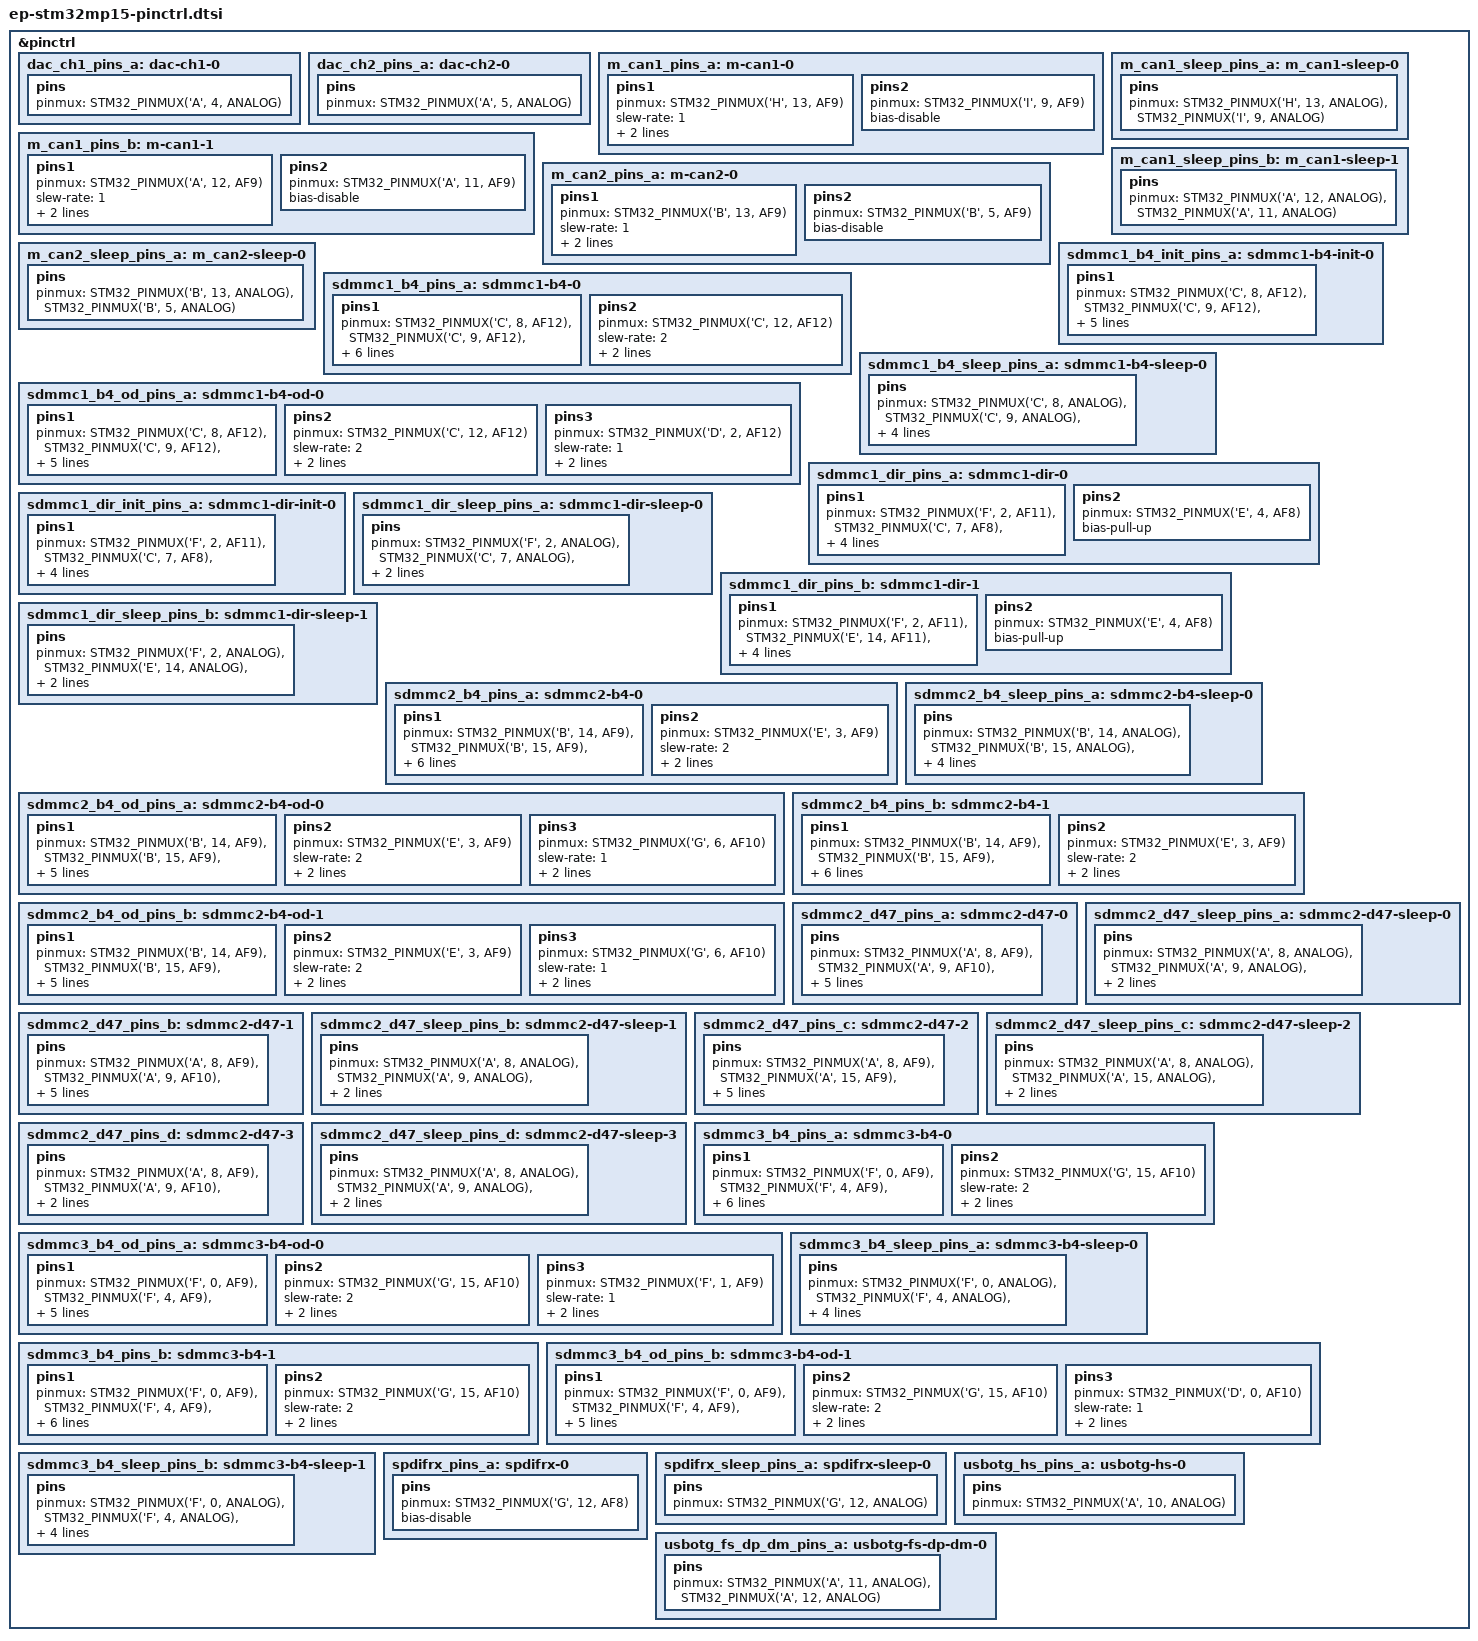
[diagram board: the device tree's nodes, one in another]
// SPDX-License-Identifier: (GPL-2.0+ OR BSD-3-Clause)
/*
 * Copyright (C) STMicroelectronics 2017 - All Rights Reserved
 * Author: Ludovic Barre <ludovic.barre@st.com> for STMicroelectronics.
 */
#include <dt-bindings/pinctrl/stm32-pinfunc.h>

&pinctrl {	
	dac_ch1_pins_a: dac-ch1-0 {
		pins {
			pinmux = <STM32_PINMUX('A', 4, ANALOG)>;
		};
	};

	dac_ch2_pins_a: dac-ch2-0 {
		pins {
			pinmux = <STM32_PINMUX('A', 5, ANALOG)>;
		};
	};
	

	m_can1_pins_a: m-can1-0 {
		pins1 {
			pinmux = <STM32_PINMUX('H', 13, AF9)>; /* CAN1_TX */
			slew-rate = <1>;
			drive-push-pull;
			bias-disable;
		};
		pins2 {
			pinmux = <STM32_PINMUX('I', 9, AF9)>; /* CAN1_RX */
			bias-disable;
		};
	};

	m_can1_sleep_pins_a: m_can1-sleep-0 {
		pins {
			pinmux = <STM32_PINMUX('H', 13, ANALOG)>, /* CAN1_TX */
				 <STM32_PINMUX('I', 9, ANALOG)>; /* CAN1_RX */
		};
	};

	m_can1_pins_b: m-can1-1 {
		pins1 {
			pinmux = <STM32_PINMUX('A', 12, AF9)>; /* CAN1_TX */
			slew-rate = <1>;
			drive-push-pull;
			bias-disable;
		};
		pins2 {
			pinmux = <STM32_PINMUX('A', 11, AF9)>; /* CAN1_RX */
			bias-disable;
		};
	};

	m_can1_sleep_pins_b: m_can1-sleep-1 {
		pins {
			pinmux = <STM32_PINMUX('A', 12, ANALOG)>, /* CAN1_TX */
				 <STM32_PINMUX('A', 11, ANALOG)>; /* CAN1_RX */
		};
	};

	m_can2_pins_a: m-can2-0 {
		pins1 {
			pinmux = <STM32_PINMUX('B', 13, AF9)>; /* CAN2_TX */
			slew-rate = <1>;
			drive-push-pull;
			bias-disable;
		};
		pins2 {
			pinmux = <STM32_PINMUX('B', 5, AF9)>; /* CAN2_RX */
			bias-disable;
		};
	};

	m_can2_sleep_pins_a: m_can2-sleep-0 {
		pins {
			pinmux = <STM32_PINMUX('B', 13, ANALOG)>, /* CAN2_TX */
				 <STM32_PINMUX('B', 5, ANALOG)>; /* CAN2_RX */
		};
	};
	

	sdmmc1_b4_pins_a: sdmmc1-b4-0 {
		pins1 {
			pinmux = <STM32_PINMUX('C', 8, AF12)>, /* SDMMC1_D0 */
				 <STM32_PINMUX('C', 9, AF12)>, /* SDMMC1_D1 */
				 <STM32_PINMUX('C', 10, AF12)>, /* SDMMC1_D2 */
				 <STM32_PINMUX('C', 11, AF12)>, /* SDMMC1_D3 */
				 <STM32_PINMUX('D', 2, AF12)>; /* SDMMC1_CMD */
			slew-rate = <1>;
			drive-push-pull;
			bias-disable;
		};
		pins2 {
			pinmux = <STM32_PINMUX('C', 12, AF12)>; /* SDMMC1_CK */
			slew-rate = <2>;
			drive-push-pull;
			bias-disable;
		};
	};

	sdmmc1_b4_od_pins_a: sdmmc1-b4-od-0 {
		pins1 {
			pinmux = <STM32_PINMUX('C', 8, AF12)>, /* SDMMC1_D0 */
				 <STM32_PINMUX('C', 9, AF12)>, /* SDMMC1_D1 */
				 <STM32_PINMUX('C', 10, AF12)>, /* SDMMC1_D2 */
				 <STM32_PINMUX('C', 11, AF12)>; /* SDMMC1_D3 */
			slew-rate = <1>;
			drive-push-pull;
			bias-disable;
		};
		pins2 {
			pinmux = <STM32_PINMUX('C', 12, AF12)>; /* SDMMC1_CK */
			slew-rate = <2>;
			drive-push-pull;
			bias-disable;
		};
		pins3 {
			pinmux = <STM32_PINMUX('D', 2, AF12)>; /* SDMMC1_CMD */
			slew-rate = <1>;
			drive-open-drain;
			bias-disable;
		};
	};

	sdmmc1_b4_init_pins_a: sdmmc1-b4-init-0 {
		pins1 {
			pinmux = <STM32_PINMUX('C', 8, AF12)>, /* SDMMC1_D0 */
				 <STM32_PINMUX('C', 9, AF12)>, /* SDMMC1_D1 */
				 <STM32_PINMUX('C', 10, AF12)>, /* SDMMC1_D2 */
				 <STM32_PINMUX('C', 11, AF12)>; /* SDMMC1_D3 */
			slew-rate = <1>;
			drive-push-pull;
			bias-disable;
		};
	};

	sdmmc1_b4_sleep_pins_a: sdmmc1-b4-sleep-0 {
		pins {
			pinmux = <STM32_PINMUX('C', 8, ANALOG)>, /* SDMMC1_D0 */
				 <STM32_PINMUX('C', 9, ANALOG)>, /* SDMMC1_D1 */
				 <STM32_PINMUX('C', 10, ANALOG)>, /* SDMMC1_D2 */
				 <STM32_PINMUX('C', 11, ANALOG)>, /* SDMMC1_D3 */
				 <STM32_PINMUX('C', 12, ANALOG)>, /* SDMMC1_CK */
				 <STM32_PINMUX('D', 2, ANALOG)>; /* SDMMC1_CMD */
		};
	};

	sdmmc1_dir_pins_a: sdmmc1-dir-0 {
		pins1 {
			pinmux = <STM32_PINMUX('F', 2, AF11)>, /* SDMMC1_D0DIR */
				 <STM32_PINMUX('C', 7, AF8)>, /* SDMMC1_D123DIR */
				 <STM32_PINMUX('B', 9, AF11)>; /* SDMMC1_CDIR */
			slew-rate = <1>;
			drive-push-pull;
			bias-pull-up;
		};
		pins2{
			pinmux = <STM32_PINMUX('E', 4, AF8)>; /* SDMMC1_CKIN */
			bias-pull-up;
		};
	};

	sdmmc1_dir_init_pins_a: sdmmc1-dir-init-0 {
		pins1 {
			pinmux = <STM32_PINMUX('F', 2, AF11)>, /* SDMMC1_D0DIR */
				 <STM32_PINMUX('C', 7, AF8)>, /* SDMMC1_D123DIR */
				 <STM32_PINMUX('B', 9, AF11)>; /* SDMMC1_CDIR */
			slew-rate = <1>;
			drive-push-pull;
			bias-pull-up;
		};
	};

	sdmmc1_dir_sleep_pins_a: sdmmc1-dir-sleep-0 {
		pins {
			pinmux = <STM32_PINMUX('F', 2, ANALOG)>, /* SDMMC1_D0DIR */
				 <STM32_PINMUX('C', 7, ANALOG)>, /* SDMMC1_D123DIR */
				 <STM32_PINMUX('B', 9, ANALOG)>, /* SDMMC1_CDIR */
				 <STM32_PINMUX('E', 4, ANALOG)>; /* SDMMC1_CKIN */
		};
	};

	sdmmc1_dir_pins_b: sdmmc1-dir-1 {
		pins1 {
			pinmux = <STM32_PINMUX('F', 2, AF11)>, /* SDMMC1_D0DIR */
				 <STM32_PINMUX('E', 14, AF11)>, /* SDMMC1_D123DIR */
				 <STM32_PINMUX('B', 9, AF11)>; /* SDMMC1_CDIR */
			slew-rate = <1>;
			drive-push-pull;
			bias-pull-up;
		};
		pins2{
			pinmux = <STM32_PINMUX('E', 4, AF8)>; /* SDMMC1_CKIN */
			bias-pull-up;
		};
	};

	sdmmc1_dir_sleep_pins_b: sdmmc1-dir-sleep-1 {
		pins {
			pinmux = <STM32_PINMUX('F', 2, ANALOG)>, /* SDMMC1_D0DIR */
				 <STM32_PINMUX('E', 14, ANALOG)>, /* SDMMC1_D123DIR */
				 <STM32_PINMUX('B', 9, ANALOG)>, /* SDMMC1_CDIR */
				 <STM32_PINMUX('E', 4, ANALOG)>; /* SDMMC1_CKIN */
		};
	};

	sdmmc2_b4_pins_a: sdmmc2-b4-0 {
		pins1 {
			pinmux = <STM32_PINMUX('B', 14, AF9)>, /* SDMMC2_D0 */
				 <STM32_PINMUX('B', 15, AF9)>, /* SDMMC2_D1 */
				 <STM32_PINMUX('B', 3, AF9)>, /* SDMMC2_D2 */
				 <STM32_PINMUX('B', 4, AF9)>, /* SDMMC2_D3 */
				 <STM32_PINMUX('G', 6, AF10)>; /* SDMMC2_CMD */
			slew-rate = <1>;
			drive-push-pull;
			bias-pull-up;
		};
		pins2 {
			pinmux = <STM32_PINMUX('E', 3, AF9)>; /* SDMMC2_CK */
			slew-rate = <2>;
			drive-push-pull;
			bias-pull-up;
		};
	};

	sdmmc2_b4_od_pins_a: sdmmc2-b4-od-0 {
		pins1 {
			pinmux = <STM32_PINMUX('B', 14, AF9)>, /* SDMMC2_D0 */
				 <STM32_PINMUX('B', 15, AF9)>, /* SDMMC2_D1 */
				 <STM32_PINMUX('B', 3, AF9)>, /* SDMMC2_D2 */
				 <STM32_PINMUX('B', 4, AF9)>; /* SDMMC2_D3 */
			slew-rate = <1>;
			drive-push-pull;
			bias-pull-up;
		};
		pins2 {
			pinmux = <STM32_PINMUX('E', 3, AF9)>; /* SDMMC2_CK */
			slew-rate = <2>;
			drive-push-pull;
			bias-pull-up;
		};
		pins3 {
			pinmux = <STM32_PINMUX('G', 6, AF10)>; /* SDMMC2_CMD */
			slew-rate = <1>;
			drive-open-drain;
			bias-pull-up;
		};
	};

	sdmmc2_b4_sleep_pins_a: sdmmc2-b4-sleep-0 {
		pins {
			pinmux = <STM32_PINMUX('B', 14, ANALOG)>, /* SDMMC2_D0 */
				 <STM32_PINMUX('B', 15, ANALOG)>, /* SDMMC2_D1 */
				 <STM32_PINMUX('B', 3, ANALOG)>, /* SDMMC2_D2 */
				 <STM32_PINMUX('B', 4, ANALOG)>, /* SDMMC2_D3 */
				 <STM32_PINMUX('E', 3, ANALOG)>, /* SDMMC2_CK */
				 <STM32_PINMUX('G', 6, ANALOG)>; /* SDMMC2_CMD */
		};
	};

	sdmmc2_b4_pins_b: sdmmc2-b4-1 {
		pins1 {
			pinmux = <STM32_PINMUX('B', 14, AF9)>, /* SDMMC2_D0 */
				 <STM32_PINMUX('B', 15, AF9)>, /* SDMMC2_D1 */
				 <STM32_PINMUX('B', 3, AF9)>, /* SDMMC2_D2 */
				 <STM32_PINMUX('B', 4, AF9)>, /* SDMMC2_D3 */
				 <STM32_PINMUX('G', 6, AF10)>; /* SDMMC2_CMD */
			slew-rate = <1>;
			drive-push-pull;
			bias-disable;
		};
		pins2 {
			pinmux = <STM32_PINMUX('E', 3, AF9)>; /* SDMMC2_CK */
			slew-rate = <2>;
			drive-push-pull;
			bias-disable;
		};
	};

	sdmmc2_b4_od_pins_b: sdmmc2-b4-od-1 {
		pins1 {
			pinmux = <STM32_PINMUX('B', 14, AF9)>, /* SDMMC2_D0 */
				 <STM32_PINMUX('B', 15, AF9)>, /* SDMMC2_D1 */
				 <STM32_PINMUX('B', 3, AF9)>, /* SDMMC2_D2 */
				 <STM32_PINMUX('B', 4, AF9)>; /* SDMMC2_D3 */
			slew-rate = <1>;
			drive-push-pull;
			bias-disable;
		};
		pins2 {
			pinmux = <STM32_PINMUX('E', 3, AF9)>; /* SDMMC2_CK */
			slew-rate = <2>;
			drive-push-pull;
			bias-disable;
		};
		pins3 {
			pinmux = <STM32_PINMUX('G', 6, AF10)>; /* SDMMC2_CMD */
			slew-rate = <1>;
			drive-open-drain;
			bias-disable;
		};
	};

	sdmmc2_d47_pins_a: sdmmc2-d47-0 {
		pins {
			pinmux = <STM32_PINMUX('A', 8, AF9)>, /* SDMMC2_D4 */
				 <STM32_PINMUX('A', 9, AF10)>, /* SDMMC2_D5 */
				 <STM32_PINMUX('E', 5, AF9)>, /* SDMMC2_D6 */
				 <STM32_PINMUX('D', 3, AF9)>; /* SDMMC2_D7 */
			slew-rate = <1>;
			drive-push-pull;
			bias-pull-up;
		};
	};

	sdmmc2_d47_sleep_pins_a: sdmmc2-d47-sleep-0 {
		pins {
			pinmux = <STM32_PINMUX('A', 8, ANALOG)>, /* SDMMC2_D4 */
				 <STM32_PINMUX('A', 9, ANALOG)>, /* SDMMC2_D5 */
				 <STM32_PINMUX('E', 5, ANALOG)>, /* SDMMC2_D6 */
				 <STM32_PINMUX('D', 3, ANALOG)>; /* SDMMC2_D7 */
		};
	};

	sdmmc2_d47_pins_b: sdmmc2-d47-1 {
		pins {
			pinmux = <STM32_PINMUX('A', 8, AF9)>,  /* SDMMC2_D4 */
				 <STM32_PINMUX('A', 9, AF10)>, /* SDMMC2_D5 */
				 <STM32_PINMUX('C', 6, AF10)>, /* SDMMC2_D6 */
				 <STM32_PINMUX('C', 7, AF10)>; /* SDMMC2_D7 */
			slew-rate = <1>;
			drive-push-pull;
			bias-disable;
		};
	};

	sdmmc2_d47_sleep_pins_b: sdmmc2-d47-sleep-1 {
		pins {
			pinmux = <STM32_PINMUX('A', 8, ANALOG)>, /* SDMMC2_D4 */
				 <STM32_PINMUX('A', 9, ANALOG)>, /* SDMMC2_D5 */
				 <STM32_PINMUX('C', 6, ANALOG)>, /* SDMMC2_D6 */
				 <STM32_PINMUX('C', 7, ANALOG)>; /* SDMMC2_D7 */
		};
	};

	sdmmc2_d47_pins_c: sdmmc2-d47-2 {
		pins {
			pinmux = <STM32_PINMUX('A', 8, AF9)>, /* SDMMC2_D4 */
				 <STM32_PINMUX('A', 15, AF9)>, /* SDMMC2_D5 */
				 <STM32_PINMUX('C', 6, AF10)>, /* SDMMC2_D6 */
				 <STM32_PINMUX('C', 7, AF10)>; /* SDMMC2_D7 */
			slew-rate = <1>;
			drive-push-pull;
			bias-pull-up;
		};
	};

	sdmmc2_d47_sleep_pins_c: sdmmc2-d47-sleep-2 {
		pins {
			pinmux = <STM32_PINMUX('A', 8, ANALOG)>, /* SDMMC2_D4 */
				 <STM32_PINMUX('A', 15, ANALOG)>, /* SDMMC2_D5 */
				 <STM32_PINMUX('C', 6, ANALOG)>, /* SDMMC2_D6 */
				 <STM32_PINMUX('C', 7, ANALOG)>; /* SDMMC2_D7 */
		};
	};

	sdmmc2_d47_pins_d: sdmmc2-d47-3 {
		pins {
			pinmux = <STM32_PINMUX('A', 8, AF9)>, /* SDMMC2_D4 */
				 <STM32_PINMUX('A', 9, AF10)>, /* SDMMC2_D5 */
				 <STM32_PINMUX('E', 5, AF9)>, /* SDMMC2_D6 */
				 <STM32_PINMUX('C', 7, AF10)>; /* SDMMC2_D7 */
		};
	};

	sdmmc2_d47_sleep_pins_d: sdmmc2-d47-sleep-3 {
		pins {
			pinmux = <STM32_PINMUX('A', 8, ANALOG)>, /* SDMMC2_D4 */
				 <STM32_PINMUX('A', 9, ANALOG)>, /* SDMMC2_D5 */
				 <STM32_PINMUX('E', 5, ANALOG)>, /* SDMMC2_D6 */
				 <STM32_PINMUX('C', 7, ANALOG)>; /* SDMMC2_D7 */
		};
	};

	sdmmc3_b4_pins_a: sdmmc3-b4-0 {
		pins1 {
			pinmux = <STM32_PINMUX('F', 0, AF9)>, /* SDMMC3_D0 */
				 <STM32_PINMUX('F', 4, AF9)>, /* SDMMC3_D1 */
				 <STM32_PINMUX('F', 5, AF9)>, /* SDMMC3_D2 */
				 <STM32_PINMUX('D', 7, AF10)>, /* SDMMC3_D3 */
				 <STM32_PINMUX('F', 1, AF9)>; /* SDMMC3_CMD */
			slew-rate = <1>;
			drive-push-pull;
			bias-pull-up;
		};
		pins2 {
			pinmux = <STM32_PINMUX('G', 15, AF10)>; /* SDMMC3_CK */
			slew-rate = <2>;
			drive-push-pull;
			bias-pull-up;
		};
	};

	sdmmc3_b4_od_pins_a: sdmmc3-b4-od-0 {
		pins1 {
			pinmux = <STM32_PINMUX('F', 0, AF9)>, /* SDMMC3_D0 */
				 <STM32_PINMUX('F', 4, AF9)>, /* SDMMC3_D1 */
				 <STM32_PINMUX('F', 5, AF9)>, /* SDMMC3_D2 */
				 <STM32_PINMUX('D', 7, AF10)>; /* SDMMC3_D3 */
			slew-rate = <1>;
			drive-push-pull;
			bias-pull-up;
		};
		pins2 {
			pinmux = <STM32_PINMUX('G', 15, AF10)>; /* SDMMC3_CK */
			slew-rate = <2>;
			drive-push-pull;
			bias-pull-up;
		};
		pins3 {
			pinmux = <STM32_PINMUX('F', 1, AF9)>; /* SDMMC2_CMD */
			slew-rate = <1>;
			drive-open-drain;
			bias-pull-up;
		};
	};

	sdmmc3_b4_sleep_pins_a: sdmmc3-b4-sleep-0 {
		pins {
			pinmux = <STM32_PINMUX('F', 0, ANALOG)>, /* SDMMC3_D0 */
				 <STM32_PINMUX('F', 4, ANALOG)>, /* SDMMC3_D1 */
				 <STM32_PINMUX('F', 5, ANALOG)>, /* SDMMC3_D2 */
				 <STM32_PINMUX('D', 7, ANALOG)>, /* SDMMC3_D3 */
				 <STM32_PINMUX('G', 15, ANALOG)>, /* SDMMC3_CK */
				 <STM32_PINMUX('F', 1, ANALOG)>; /* SDMMC3_CMD */
		};
	};

	sdmmc3_b4_pins_b: sdmmc3-b4-1 {
		pins1 {
			pinmux = <STM32_PINMUX('F', 0, AF9)>, /* SDMMC3_D0 */
				 <STM32_PINMUX('F', 4, AF9)>, /* SDMMC3_D1 */
				 <STM32_PINMUX('D', 5, AF10)>, /* SDMMC3_D2 */
				 <STM32_PINMUX('D', 7, AF10)>, /* SDMMC3_D3 */
				 <STM32_PINMUX('D', 0, AF10)>; /* SDMMC3_CMD */
			slew-rate = <1>;
			drive-push-pull;
			bias-pull-up;
		};
		pins2 {
			pinmux = <STM32_PINMUX('G', 15, AF10)>; /* SDMMC3_CK */
			slew-rate = <2>;
			drive-push-pull;
			bias-pull-up;
		};
	};

	sdmmc3_b4_od_pins_b: sdmmc3-b4-od-1 {
		pins1 {
			pinmux = <STM32_PINMUX('F', 0, AF9)>, /* SDMMC3_D0 */
				 <STM32_PINMUX('F', 4, AF9)>, /* SDMMC3_D1 */
				 <STM32_PINMUX('D', 5, AF10)>, /* SDMMC3_D2 */
				 <STM32_PINMUX('D', 7, AF10)>; /* SDMMC3_D3 */
			slew-rate = <1>;
			drive-push-pull;
			bias-pull-up;
		};
		pins2 {
			pinmux = <STM32_PINMUX('G', 15, AF10)>; /* SDMMC3_CK */
			slew-rate = <2>;
			drive-push-pull;
			bias-pull-up;
		};
		pins3 {
			pinmux = <STM32_PINMUX('D', 0, AF10)>; /* SDMMC2_CMD */
			slew-rate = <1>;
			drive-open-drain;
			bias-pull-up;
		};
	};

	sdmmc3_b4_sleep_pins_b: sdmmc3-b4-sleep-1 {
		pins {
			pinmux = <STM32_PINMUX('F', 0, ANALOG)>, /* SDMMC3_D0 */
				 <STM32_PINMUX('F', 4, ANALOG)>, /* SDMMC3_D1 */
				 <STM32_PINMUX('D', 5, ANALOG)>, /* SDMMC3_D2 */
				 <STM32_PINMUX('D', 7, ANALOG)>, /* SDMMC3_D3 */
				 <STM32_PINMUX('G', 15, ANALOG)>, /* SDMMC3_CK */
				 <STM32_PINMUX('D', 0, ANALOG)>; /* SDMMC3_CMD */
		};
	};

	spdifrx_pins_a: spdifrx-0 {
		pins {
			pinmux = <STM32_PINMUX('G', 12, AF8)>; /* SPDIF_IN1 */
			bias-disable;
		};
	};

	spdifrx_sleep_pins_a: spdifrx-sleep-0 {
		pins {
			pinmux = <STM32_PINMUX('G', 12, ANALOG)>; /* SPDIF_IN1 */
		};
	};	

	usbotg_hs_pins_a: usbotg-hs-0 {
		pins {
			pinmux = <STM32_PINMUX('A', 10, ANALOG)>; /* OTG_ID */
		};
	};

	usbotg_fs_dp_dm_pins_a: usbotg-fs-dp-dm-0 {
		pins {
			pinmux = <STM32_PINMUX('A', 11, ANALOG)>, /* OTG_FS_DM */
				 <STM32_PINMUX('A', 12, ANALOG)>; /* OTG_FS_DP */
		};
	};
};

